AUTOSAR XML (schema 4-0-3)
package /ComponentTypes
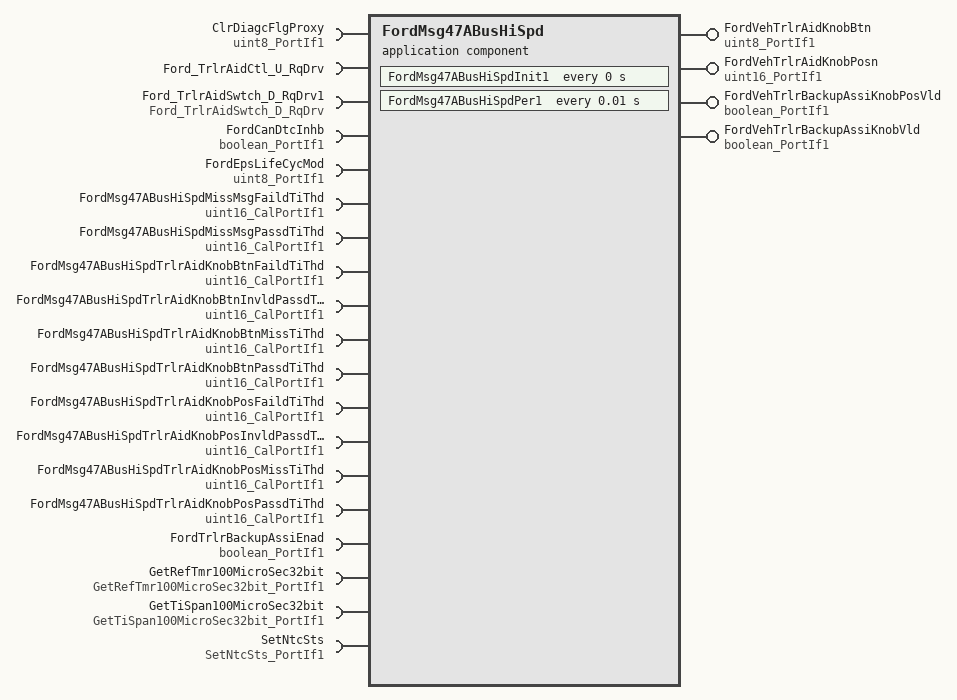
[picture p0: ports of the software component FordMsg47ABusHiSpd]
  application sw component type FordMsg47ABusHiSpd
    4 x provide port:
      FordVehTrlrAidKnobBtn: nonqueued-sender-com-spec{data-element=Val, init-value=0}, provided-interface=uint8_PortIf1
      FordVehTrlrAidKnobPosn: nonqueued-sender-com-spec{data-element=Val, init-value=0}, provided-interface=uint16_PortIf1
      FordVehTrlrBackupAssiKnobPosVld: nonqueued-sender-com-spec{data-element=Logl, init-value=0}, provided-interface=boolean_PortIf1
      FordVehTrlrBackupAssiKnobVld: nonqueued-sender-com-spec{data-element=Logl, init-value=0}, provided-interface=boolean_PortIf1
    19 x require port:
      ClrDiagcFlgProxy: nonqueued-receiver-com-spec{data-element=Val, filter=data-filter-type=ALWAYS, init-value=0}, required-interface=uint8_PortIf1
      Ford_TrlrAidCtl_U_RqDrv: nonqueued-receiver-com-spec{data-element=Ford_TrlrAidCtl_U_RqDrv, filter=data-filter-type=ALWAYS, init-value=0}, required-interface=Ford_TrlrAidCtl_U_RqDrv
      Ford_TrlrAidSwtch_D_RqDrv1: nonqueued-receiver-com-spec{data-element=Ford_TrlrAidSwtch_D_RqDrv, filter=data-filter-type=ALWAYS, init-value=0}, required-interface=Ford_TrlrAidSwtch_D_RqDrv
      FordCanDtcInhb: nonqueued-receiver-com-spec{data-element=Logl, filter=data-filter-type=ALWAYS, init-value=1}, required-interface=boolean_PortIf1
      FordEpsLifeCycMod: nonqueued-receiver-com-spec{data-element=Val, filter=data-filter-type=ALWAYS, init-value=0}, required-interface=uint8_PortIf1
      FordMsg47ABusHiSpdMissMsgFaildTiThd: parameter-require-com-spec{init-value=100, parameter=Val}, required-interface=uint16_CalPortIf1
      FordMsg47ABusHiSpdMissMsgPassdTiThd: parameter-require-com-spec{init-value=0, parameter=Val}, required-interface=uint16_CalPortIf1
      FordMsg47ABusHiSpdTrlrAidKnobBtnFaildTiThd: parameter-require-com-spec{init-value=0, parameter=Val}, required-interface=uint16_CalPortIf1
      FordMsg47ABusHiSpdTrlrAidKnobBtnInvldPassdTiThd: parameter-require-com-spec{init-value=0, parameter=Val}, required-interface=uint16_CalPortIf1
      FordMsg47ABusHiSpdTrlrAidKnobBtnMissTiThd: parameter-require-com-spec{init-value=100, parameter=Val}, required-interface=uint16_CalPortIf1
      FordMsg47ABusHiSpdTrlrAidKnobBtnPassdTiThd: parameter-require-com-spec{init-value=100, parameter=Val}, required-interface=uint16_CalPortIf1
      FordMsg47ABusHiSpdTrlrAidKnobPosFaildTiThd: parameter-require-com-spec{init-value=0, parameter=Val}, required-interface=uint16_CalPortIf1
      FordMsg47ABusHiSpdTrlrAidKnobPosInvldPassdTiThd: parameter-require-com-spec{init-value=0, parameter=Val}, required-interface=uint16_CalPortIf1
      FordMsg47ABusHiSpdTrlrAidKnobPosMissTiThd: parameter-require-com-spec{init-value=100, parameter=Val}, required-interface=uint16_CalPortIf1
      FordMsg47ABusHiSpdTrlrAidKnobPosPassdTiThd: parameter-require-com-spec{init-value=100, parameter=Val}, required-interface=uint16_CalPortIf1
      FordTrlrBackupAssiEnad: nonqueued-receiver-com-spec{data-element=Logl, filter=data-filter-type=ALWAYS, init-value=0}, required-interface=boolean_PortIf1
      GetRefTmr100MicroSec32bit: client-com-spec=Oper, required-interface=GetRefTmr100MicroSec32bit_PortIf1
      GetTiSpan100MicroSec32bit: client-com-spec=Oper, required-interface=GetTiSpan100MicroSec32bit_PortIf1
      SetNtcSts: client-com-spec=Oper, required-interface=SetNtcSts_PortIf1
    behavior FordMsg47ABusHiSpd_InternalBehavior
      ar-typed-per-instance-memorys:
        21 x data, all with sw-calibration-access=READ-ONLY:
          ClrDiagcFlgProxyPrev: type=uint8
          FirstTranTrlrAidKnobBtnVldFlg: type=boolean
          FirstTranTrlrAidKnobPosVldFlg: type=boolean
          FordVehMsg47Miss: type=boolean
          FordVehMsg47Rxd: type=boolean
          FordVehTrlrAidKnobBtnInvldFaildRefTi: type=uint32
          FordVehTrlrAidKnobBtnInvldPassdRefTi: type=uint32
          FordVehTrlrAidKnobBtnPrev: type=Ford_TrlrAidSwtch_D_RqDrv
          FordVehTrlrAidKnobPosnInvldFaildRefTi: type=uint32
          FordVehTrlrAidKnobPosnInvldPassdRefTi: type=uint32
          FordVehTrlrAidKnobPosnPrev: type=uint16
          MissMsgFaildRefTi: type=uint32
          MissMsgPassdRefTi: type=uint32
          TrlrAidKnobBtnVldFaildRefTi: type=uint32
          TrlrAidKnobBtnVldMissRefTi: type=uint32
          TrlrAidKnobBtnVldPassdRefTi: type=uint32
          TrlrAidKnobBtnVldPrev: type=boolean
          TrlrAidKnobPosVldFaildRefTi: type=uint32
          TrlrAidKnobPosVldMissRefTi: type=uint32
          TrlrAidKnobPosVldPassdRefTi: type=uint32
          TrlrAidKnobPosVldPrev: type=boolean
      timing event FordMsg47ABusHiSpdInit1_InitEvent: start-on-event=FordMsg47ABusHiSpdInit1, period=0
      timing event TMT_FordMsg47ABusHiSpdPer1: start-on-event=FordMsg47ABusHiSpdPer1, period=0.01
      port-api-options:
        enable-take-address=false, indirect-api=false, port=ClrDiagcFlgProxy
        enable-take-address=false, indirect-api=false, port=Ford_TrlrAidCtl_U_RqDrv
        enable-take-address=false, indirect-api=false, port=Ford_TrlrAidSwtch_D_RqDrv1
        enable-take-address=false, indirect-api=false, port=FordCanDtcInhb
        enable-take-address=false, indirect-api=false, port=FordEpsLifeCycMod
        enable-take-address=false, indirect-api=false, port=FordMsg47ABusHiSpdMissMsgFaildTiThd
        enable-take-address=false, indirect-api=false, port=FordMsg47ABusHiSpdMissMsgPassdTiThd
        enable-take-address=false, indirect-api=false, port=FordMsg47ABusHiSpdTrlrAidKnobBtnFaildTiThd
        enable-take-address=false, indirect-api=false, port=FordMsg47ABusHiSpdTrlrAidKnobBtnInvldPassdTiThd
        enable-take-address=false, indirect-api=false, port=FordMsg47ABusHiSpdTrlrAidKnobBtnMissTiThd
        enable-take-address=false, indirect-api=false, port=FordMsg47ABusHiSpdTrlrAidKnobBtnPassdTiThd
        enable-take-address=false, indirect-api=false, port=FordMsg47ABusHiSpdTrlrAidKnobPosFaildTiThd
        enable-take-address=false, indirect-api=false, port=FordMsg47ABusHiSpdTrlrAidKnobPosInvldPassdTiThd
        enable-take-address=false, indirect-api=false, port=FordMsg47ABusHiSpdTrlrAidKnobPosMissTiThd
        enable-take-address=false, indirect-api=false, port=FordMsg47ABusHiSpdTrlrAidKnobPosPassdTiThd
        enable-take-address=false, indirect-api=false, port=FordTrlrBackupAssiEnad
        enable-take-address=false, indirect-api=false, port=FordVehTrlrAidKnobBtn
        enable-take-address=false, indirect-api=false, port=FordVehTrlrAidKnobPosn
        enable-take-address=false, indirect-api=false, port=FordVehTrlrBackupAssiKnobPosVld
        enable-take-address=false, indirect-api=false, port=FordVehTrlrBackupAssiKnobVld
        enable-take-address=false, indirect-api=false, port=GetRefTmr100MicroSec32bit
        enable-take-address=false, indirect-api=false, port=GetTiSpan100MicroSec32bit
        enable-take-address=false, indirect-api=false, port=SetNtcSts
      runnable FordMsg47ABusHiSpdInit1
        sync call SC_GetRefTmr100MicroSec32bit_PortIf1_Oper: operation=GetRefTmr100MicroSec32bit.Oper, timeout=0
      runnable FordMsg47ABusHiSpdPer1
        data-receive-point-by-arguments:
          6 x access:
            REC_ClrDiagcFlgProxy_Val: accessed-variable=ClrDiagcFlgProxy.Val
            REC_Ford_TrlrAidCtl_U_RqDrv_Ford_TrlrAidCtl_U_RqDrv: accessed-variable=Ford_TrlrAidCtl_U_RqDrv.Ford_TrlrAidCtl_U_RqDrv
            REC_Ford_TrlrAidSwtch_D_RqDrv1_Ford_TrlrAidSwtch_D_RqDrv: accessed-variable=Ford_TrlrAidSwtch_D_RqDrv1.Ford_TrlrAidSwtch_D_RqDrv
            REC_FordCanDtcInhb_Logl: accessed-variable=FordCanDtcInhb.Logl
            REC_FordEpsLifeCycMod_Val: accessed-variable=FordEpsLifeCycMod.Val
            REC_FordTrlrBackupAssiEnad_Logl: accessed-variable=FordTrlrBackupAssiEnad.Logl
        data-send-points:
          4 x access:
            SEND_FordVehTrlrAidKnobBtn_Val: accessed-variable=FordVehTrlrAidKnobBtn.Val
            SEND_FordVehTrlrAidKnobPosn_Val: accessed-variable=FordVehTrlrAidKnobPosn.Val
            SEND_FordVehTrlrBackupAssiKnobPosVld_Logl: accessed-variable=FordVehTrlrBackupAssiKnobPosVld.Logl
            SEND_FordVehTrlrBackupAssiKnobVld_Logl: accessed-variable=FordVehTrlrBackupAssiKnobVld.Logl
        sync call SC_GetRefTmr100MicroSec32bit_PortIf1_Oper: operation=GetRefTmr100MicroSec32bit.Oper, timeout=0
        sync call SC_GetTiSpan100MicroSec32bit_Oper: operation=GetTiSpan100MicroSec32bit.Oper, timeout=0
        sync call SC_SetNtcSts_Oper: operation=SetNtcSts.Oper, timeout=0
  swc implementation FordMsg47ABusHiSpd_Implementation: behavior=FordMsg47ABusHiSpd_InternalBehavior
    code-descriptors:
      code Default: artifact-descriptors=autosar-engineering-object={short-label=Default, category=SWSRC}
